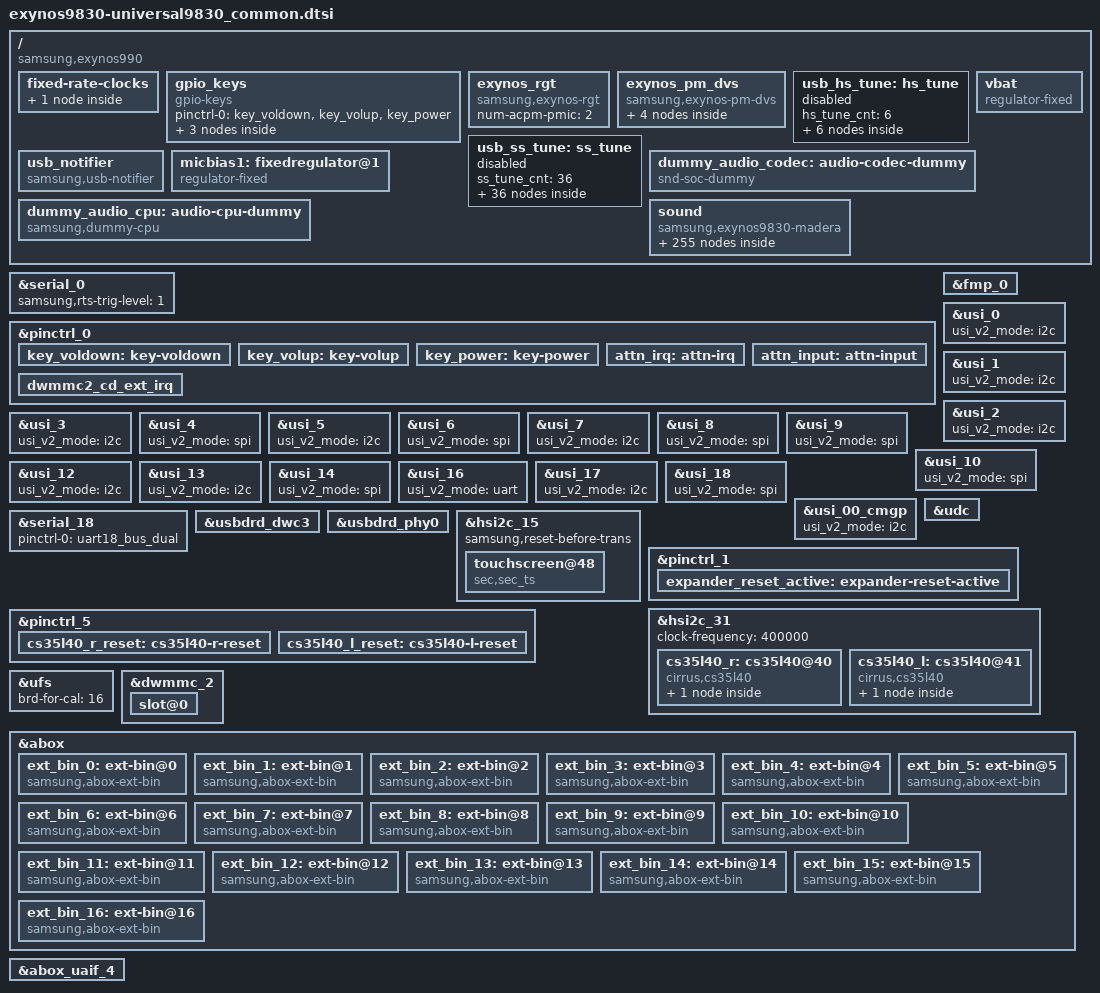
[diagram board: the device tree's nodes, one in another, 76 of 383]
/*
 * SAMSUNG EXYNOS9830 board device tree source
 *
 * Copyright (c) 2019 Samsung Electronics Co., Ltd.
 *		http://www.samsung.com
 *
 * This program is free software; you can redistribute it and/or modify
 * it under the terms of the GNU General Public License version 2 as
 * published by the Free Software Foundation.
*/

#include <dt-bindings/clock/exynos9830.h>
#include "battery_data_universal9830_max77705.dtsi"
#include "exynos9830-universal9830_if-pmic-max77705.dtsi"
#include <dt-bindings/pci/pci.h>

/ {
	compatible = "samsung,exynos990", "samsung,UNIVERSAL990";
	board_id = <0x0>;
	board_rev = <0x0>;

	fragment@model {
		target-path = "/";
		__overlay__ {
			#address-cells = <2>;
			#size-cells = <1>;

			fixed-rate-clocks {
				oscclk {
					compatible = "samsung,exynos9830-oscclk";
					clock-frequency = <26000000>;
				};
			};

			gpio_keys {
				status = "okay";
				compatible = "gpio-keys";
				pinctrl-names = "default";
				pinctrl-0 = <&key_voldown &key_volup &key_power>;

				button@2 {
					label = "gpio-keys: KEY_VOLUMEDOWN";
					linux,code = <114>;
					gpios = <&gpa0 4 0xf>;
				};
				button@3 {
					label = "gpio-keys: KEY_VOLUMEUP";
					linux,code = <115>;
					gpios = <&gpa0 3 0xf>;
				};
				button@4 {
					label = "gpio-keys: KEY_POWER";
					linux,code = <116>;
					gpios = <&gpa2 4 0xf>;
					gpio-key,wakeup = <1>;
				};
			};

			exynos_rgt {
				compatible = "samsung,exynos-rgt";
				num-acpm-pmic = <2>;
			};

			exynos_pm_dvs {
				compatible = "samsung,exynos-pm-dvs";
				vdd_lldo1 {
					regulator_name = "m_vdd_buck9";
					suspend_volt = <800000>;
					init_volt = <850000>;
					volt_range_step = <62500>;
				};

				vdd_lldo2 {
					regulator_name = "m_vdd_buck10";
					suspend_volt = <900000>;
					init_volt = <950000>;
					volt_range_step = <62500>;
				};

				vdd_lldo3 {
					regulator_name = "m_vdd_buck11";
					suspend_volt = <1250000>;
					init_volt = <1350000>;
					volt_range_step = <62500>;
				};
				vdd_mldo {
					regulator_name = "m_vdd_buck12";
					suspend_volt = <1850000>;
					init_volt = <2000000>;
					volt_range_step = <12500>;
				};
			};

			usb_hs_tune:hs_tune {
				status = "disabled";
				hs_tune_cnt = <6>;
				/* value = <device host> */
				hs_tune1 {
					tune_name = "tx_pre_emp";
					tune_value = <0x3 0x3>;
				};

				hs_tune2 {
					tune_name = "tx_vref";
					tune_value = <0xf 0xf>;
				};

				hs_tune3 {
					tune_name = "rx_sqrx";
					tune_value = <0x7 0x7>;
				};

				hs_tune4 {
					tune_name = "utmi_clk";
					tune_value = <0x1 0x1>;
				};

				hs_tune5 {
					tune_name = "compdis";
					tune_value = <0x7 0x7>;
				};

				hs_tune6 {
					tune_name = "tx_res";
					tune_value = <0x3 0x3>;
				};
			};

			usb_ss_tune:ss_tune {
				status = "disabled";
				ss_tune_cnt = <36>;
				/* value = <device host> */
				/* 0xffffffff means using default value */
				ss_tune1 {
					tune_name = "ssrx_sqhs_th_ss";
					tune_value = <0xffffffff 0xffffffff>;
				};

				ss_tune2 {
					tune_name = "ssrx_sqhs_th_ssp";
					tune_value = <0xffffffff 0xffffffff>;
				};

				ss_tune3 {
					tune_name = "ssrx_lfps_th";
					tune_value = <0xffffffff 0xffffffff>;
				};

				ss_tune4 {
					tune_name = "ssrx_adap_coef_sel";
					tune_value = <0xffffffff 0xffffffff>;
				};

				ss_tune5 {
					tune_name = "ssrx_mf_eq_psel_ctrl_ss";
					tune_value = <0xffffffff 0xffffffff>;
				};

				ss_tune6 {
					tune_name = "ssrx_mf_eq_psel_ctrl_ssp";
					tune_value = <0xffffffff 0xffffffff>;
				};

				ss_tune7 {
					tune_name = "ssrx_mf_eq_zsel_ctrl_ss";
					tune_value = <0xffffffff 0xffffffff>;
				};


				ss_tune8 {
					tune_name = "ssrx_mf_eq_zsel_ctrl_ssp";
					tune_value = <0xffffffff 0xffffffff>;
				};

				ss_tune9 {
					tune_name = "ssrx_hf_eq_rsel_ctrl_ss";
					tune_value = <0xffffffff 0xffffffff>;
				};

				ss_tune10 {
					tune_name = "ssrx_hf_eq_rsel_ctrl_ssp";
					tune_value = <0xffffffff 0xffffffff>;
				};

				ss_tune11 {
					tune_name = "ssrx_hf_eq_csel_ctrl_ss";
					tune_value = <0xffffffff 0xffffffff>;
				};

				ss_tune12 {
					tune_name = "ssrx_hf_eq_csel_ctrl_ssp";
					tune_value = <0xffffffff 0xffffffff>;
				};

				ss_tune13 {
					tune_name = "ssrx_dfe_1tap_ctrl_ss";
					tune_value = <0xffffffff 0xffffffff>;
				};

				ss_tune14 {
					tune_name = "ssrx_dfe_1tap_ctrl_ssp";
					tune_value = <0xffffffff 0xffffffff>;
				};

				ss_tune15 {
					tune_name = "ssrx_dfe_2tap_ctrl_ss";
					tune_value = <0xffffffff 0xffffffff>;
				};

				ss_tune16 {
					tune_name = "ssrx_dfe_2tap_ctrl_ssp";
					tune_value = <0xffffffff 0xffffffff>;
				};

				ss_tune17 {
					tune_name = "ssrx_dfe_3tap_ctrl_ss";
					tune_value = <0xffffffff 0xffffffff>;
				};

				ss_tune18 {
					tune_name = "ssrx_dfe_3tap_ctrl_ssp";
					tune_value = <0xffffffff 0xffffffff>;
				};

				ss_tune19 {
					tune_name = "ssrx_dfe_4tap_ctrl_ss";
					tune_value = <0xffffffff 0xffffffff>;
				};

				ss_tune20 {
					tune_name = "ssrx_dfe_4tap_ctrl_ssp";
					tune_value = <0xffffffff 0xffffffff>;
				};

				ss_tune21 {
					tune_name = "ssrx_dfe_5tap_ctrl_ss";
					tune_value = <0xffffffff 0xffffffff>;
				};

				ss_tune22 {
					tune_name = "ssrx_dfe_5tap_ctrl_ssp";
					tune_value = <0xffffffff 0xffffffff>;
				};

				ss_tune23 {
					tune_name = "ssrx_term_cal";
					tune_value = <0xffffffff 0xffffffff>;
				};

				ss_tune24 {
					tune_name = "sstx_amp_ss";
					tune_value = <0xffffffff 0xffffffff>;
				};

				ss_tune25 {
					tune_name = "sstx_deemp_ss";
					tune_value = <0xffffffff 0xffffffff>;
				};

				ss_tune26 {
					tune_name = "sstx_pre_shoot_ss";
					tune_value = <0xffffffff 0xffffffff>;
				};

				ss_tune27 {
					tune_name = "sstx_amp_ssp";
					tune_value = <0xffffffff 0xffffffff>;
				};

				ss_tune28 {
					tune_name = "sstx_deemp_ssp";
					tune_value = <0xffffffff 0xffffffff>;
				};

				ss_tune29 {
					tune_name = "sstx_pre_shoot_ssp";
					tune_value = <0xffffffff 0xffffffff>;
				};

				ss_tune30 {
					tune_name = "sstx_idrv_up";
					tune_value = <0xffffffff 0xffffffff>;
				};

				ss_tune31 {
					tune_name = "sstx_lfps_idrv_up";
					tune_value = <0xffffffff 0xffffffff>;
				};

				ss_tune32 {
					tune_name = "sstx_up_term";
					tune_value = <0xffffffff 0xffffffff>;
				};

				ss_tune33 {
					tune_name = "sstx_dn_term";
					tune_value = <0xffffffff 0xffffffff>;
				};

				ss_tune34 {
					tune_name = "rext_ovrd";
					tune_value = <0xffffffff 0xffffffff>;
				};

				ss_tune35 {
					tune_name = "ssrx_cdr_fbb_fine_ctrl_sp";
					tune_value = <0xffffffff 0xffffffff>;
				};

				ss_tune36 {
					tune_name = "ssrx_cdr_fbb_fine_ctrl_ssp";
					tune_value = <0xffffffff 0xffffffff>;
				};
			};

			usb_notifier {
				compatible = "samsung,usb-notifier";
				udc = <&udc>;

				usb-ldocontrol = <4>; /* Exynos9830 */
				disable_host_wakelock = <1>;
			};

			vbat: vbat {
				compatible = "regulator-fixed";
				regulator-name = "VBAT";
				regulator-min-microvolt = <4200000>;
				regulator-max-microvolt = <4200000>;
				regulator-boot-on;
			};

			micbias1: fixedregulator@1 {
				compatible = "regulator-fixed";
				regulator-name = "main_micbias_1p8";
				regulator-min-microvolt = <1800000>;
				regulator-max-microvolt = <1800000>;
				gpio = <&gpp2 7 0>;
				enable-active-high;
				vin-supply = <&buck12_reg>;
			};

			dummy_audio_codec: audio-codec-dummy {
				compatible = "snd-soc-dummy";
				#sound-dai-cells = <0>;
			};

			dummy_audio_cpu: audio-cpu-dummy {
				compatible = "samsung,dummy-cpu";
				#sound-dai-cells = <0>;
			};

			sound {
				compatible = "samsung,exynos9830-madera";

				clock-names = "xclkout";
				clocks = <&clock OSC_AUD>;

				MICBIAS1-supply = <&micbias1>;
				MICBIAS2-supply = <&ldo13_reg>;
				MICBIAS3-supply = <&ldo14_reg>;
				MICBIAS4-supply = <&ldo17_reg>;

				samsung,routing =
					"DMIC1", "MICBIAS1",
					"DMIC2", "MICBIAS2",
					"DMIC3", "MICBIAS3",
					"DMIC4", "MICBIAS4",
					"RECEIVER", "Left AMP SPK",
					"SPEAKER", "Right AMP SPK",
					"BLUETOOTH SPK", "ABOX UAIF3 Playback",
					"ABOX UAIF3 Capture", "BLUETOOTH MIC",
					"USB SPK", "ABOX USB Playback",
					"ABOX USB Capture", "USB MIC",
					"FWD SPK", "ABOX FWD Playback",
					"ABOX FWD Capture", "FWD MIC",
					"VTS Virtual Output", "VTS Virtual Output Mux",
					"PAD DPDM", "DMIC1",
					"PAD DPDM", "DMIC2",
					"PAD DPDM", "DMIC3",
					"PAD DPDM", "DMIC4";
				samsung,codec = <&cs35l40_l &cs35l40_r &vts>;
				samsung,prefix = "Left", "Right", "VTS";
				samsung,aux = <&abox_effect &abox_tplg>;

				rdma0 {
					cpu {
						sound-dai = <&abox_rdma_0 0>;
					};
					platform {
						sound-dai = <&abox_rdma_0 0>;
					};
					codec {
						sound-dai = <&dummy_audio_codec>;
					};
				};
				rdma1 {
					cpu {
						sound-dai = <&abox_rdma_1 0>;
					};
					platform {
						sound-dai = <&abox_rdma_1 0>;
					};
					codec {
						sound-dai = <&dummy_audio_codec>;
					};
				};
				rdma2 {
					cpu {
						sound-dai = <&abox_rdma_2 0>;
					};
					platform {
						sound-dai = <&abox_rdma_2 0>;
					};
					codec {
						sound-dai = <&dummy_audio_codec>;
					};
				};
				rdma3 {
					cpu {
						sound-dai = <&abox_rdma_3 0>;
					};
					platform {
						sound-dai = <&abox_rdma_3 0>;
					};
					codec {
						sound-dai = <&dummy_audio_codec>;
					};
				};
				rdma4 {
					cpu {
						sound-dai = <&abox_rdma_4 0>;
					};
					platform {
						sound-dai = <&abox_rdma_4 0>;
					};
					codec {
						sound-dai = <&dummy_audio_codec>;
					};
				};
				rdma5 {
					cpu {
						sound-dai = <&abox_rdma_5 0>;
					};
					platform {
						sound-dai = <&abox_rdma_5 0>;
					};
					codec {
						sound-dai = <&dummy_audio_codec>;
					};
				};
				rdma6 {
					cpu {
						sound-dai = <&abox_rdma_6 0>;
					};
					platform {
						sound-dai = <&abox_rdma_6 0>;
					};
					codec {
						sound-dai = <&dummy_audio_codec>;
					};
				};
				rdma7 {
					cpu {
						sound-dai = <&abox_rdma_7 0>;
					};
					platform {
						sound-dai = <&abox_rdma_7 0>;
					};
					codec {
						sound-dai = <&dummy_audio_codec>;
					};
				};
				rdma8 {
					cpu {
						sound-dai = <&abox_rdma_8 0>;
					};
					platform {
						sound-dai = <&abox_rdma_8 0>;
					};
					codec {
						sound-dai = <&dummy_audio_codec>;
					};
				};
				rdma9 {
					cpu {
						sound-dai = <&abox_rdma_9 0>;
					};
					platform {
						sound-dai = <&abox_rdma_9 0>;
					};
					codec {
						sound-dai = <&dummy_audio_codec>;
					};
				};
				rdma10 {
					cpu {
						sound-dai = <&abox_rdma_10 0>;
					};
					platform {
						sound-dai = <&abox_rdma_10 0>;
					};
					codec {
						sound-dai = <&dummy_audio_codec>;
					};
				};
				rdma11 {
					cpu {
						sound-dai = <&abox_rdma_11 0>;
					};
					platform {
						sound-dai = <&abox_rdma_11 0>;
					};
					codec {
						sound-dai = <&dummy_audio_codec>;
					};
				};
				wdma0 {
					cpu {
						sound-dai = <&abox_wdma_0 0>;
					};
					platform {
						sound-dai = <&abox_wdma_0 0>;
					};
					codec {
						sound-dai = <&dummy_audio_codec>;
					};
				};
				wdma1 {
					cpu {
						sound-dai = <&abox_wdma_1 0>;
					};
					platform {
						sound-dai = <&abox_wdma_1 0>;
					};
					codec {
						sound-dai = <&dummy_audio_codec>;
					};
				};
				wdma2 {
					cpu {
						sound-dai = <&abox_wdma_2 0>;
					};
					platform {
						sound-dai = <&abox_wdma_2 0>;
					};
					codec {
						sound-dai = <&dummy_audio_codec>;
					};
				};
				wdma3 {
					cpu {
						sound-dai = <&abox_wdma_3 0>;
					};
					platform {
						sound-dai = <&abox_wdma_3 0>;
					};
					codec {
						sound-dai = <&dummy_audio_codec>;
					};
				};
				wdma4 {
					cpu {
						sound-dai = <&abox_wdma_4 0>;
					};
					platform {
						sound-dai = <&abox_wdma_4 0>;
					};
					codec {
						sound-dai = <&dummy_audio_codec>;
					};
				};
				vts0 {
					cpu {
						sound-dai = <&vts 0>;
					};
					codec {
						sound-dai = <&dummy_audio_codec>;
					};
				};
				vts1 {
					cpu {
						sound-dai = <&vts 1>;
					};
					codec {
						sound-dai = <&dummy_audio_codec>;
					};
				};
				dp0_audio {
					cpu {
						sound-dai = <&displayport_adma 0>;
					};
					codec {
						sound-dai = <&dummy_audio_codec>;
					};
				};
				dp1_audio {
					cpu {
						sound-dai = <&displayport_adma 1 >;
					};
					codec {
						sound-dai = <&dummy_audio_codec>;
					};
				};
				dual0 {
					cpu {
						sound-dai = <&abox_dual_0>;
					};
					platform {
						sound-dai = <&abox_dual_0>;
					};
					codec {
						sound-dai = <&dummy_audio_codec>;
					};
				};
				dual1 {
					cpu {
						sound-dai = <&abox_dual_1>;
					};
					platform {
						sound-dai = <&abox_dual_1>;
					};
					codec {
						sound-dai = <&dummy_audio_codec>;
					};
				};
				dual2 {
					cpu {
						sound-dai = <&abox_dual_2>;
					};
					platform {
						sound-dai = <&abox_dual_2>;
					};
					codec {
						sound-dai = <&dummy_audio_codec>;
					};
				};
				dual3 {
					cpu {
						sound-dai = <&abox_dual_3>;
					};
					platform {
						sound-dai = <&abox_dual_3>;
					};
					codec {
						sound-dai = <&dummy_audio_codec>;
					};
				};
				dual4 {
					cpu {
						sound-dai = <&abox_dual_4>;
					};
					platform {
						sound-dai = <&abox_dual_4>;
					};
					codec {
						sound-dai = <&dummy_audio_codec>;
					};
				};
				ddma0 {
					cpu {
						sound-dai = <&abox_ddma_0>;
					};
					platform {
						sound-dai = <&abox_ddma_0>;
					};
					codec {
						sound-dai = <&dummy_audio_codec>;
					};
				};
				ddma1 {
					cpu {
						sound-dai = <&abox_ddma_1>;
					};
					platform {
						sound-dai = <&abox_ddma_1>;
					};
					codec {
						sound-dai = <&dummy_audio_codec>;
					};
				};
				ddma2 {
					cpu {
						sound-dai = <&abox_ddma_2>;
					};
					platform {
						sound-dai = <&abox_ddma_2>;
					};
					codec {
						sound-dai = <&dummy_audio_codec>;
					};
				};
				ddma3 {
					cpu {
						sound-dai = <&abox_ddma_3>;
					};
					platform {
						sound-dai = <&abox_ddma_3>;
					};
					codec {
						sound-dai = <&dummy_audio_codec>;
					};
				};
				ddma4 {
					cpu {
						sound-dai = <&abox_ddma_4>;
					};
					platform {
						sound-dai = <&abox_ddma_4>;
					};
					codec {
						sound-dai = <&dummy_audio_codec>;
					};
				};
				ddma5 {
					cpu {
						sound-dai = <&abox_ddma_5>;
					};
					platform {
						sound-dai = <&abox_ddma_5>;
					};
					codec {
						sound-dai = <&dummy_audio_codec>;
					};
				};
				uaif0 {
					format = "i2s";
					cpu {
						sound-dai = <&abox_uaif_0>;
					};
					codec {
						sound-dai = <&dummy_audio_codec>;
					};
				};
				uaif1 {
					format = "i2s";
					cpu {
						sound-dai = <&abox_uaif_1>;
					};
					codec {
						sound-dai = <&dummy_audio_codec>;
					};
				};
				uaif2 {
					format = "dsp_a";
					cpu {
						sound-dai = <&abox_uaif_2>;
					};
					codec {
						sound-dai = <&cs35l40_l 0 &cs35l40_r 0>;
					};
				};
				uaif3 {
					format = "i2s";
					cpu {
						sound-dai = <&abox_uaif_3>;
					};
					codec {
						sound-dai = <&dummy_audio_codec>;
					};
				};
				uaif4 {
					format = "i2s";
					cpu {
						sound-dai = <&abox_uaif_4>;
					};
					codec {
						sound-dai = <&dummy_audio_codec>;
					};
				};
				uaif5 {
					format = "i2s";
					cpu {
						sound-dai = <&abox_uaif_5>;
					};
					codec {
						sound-dai = <&dummy_audio_codec>;
					};
				};
				uaif6 {
					format = "dsp_a";
					bitclock-master;
					bitclock-inversion;
					frame-master;

					cpu {
						sound-dai = <&abox_uaif_6>;
					};
					codec {
						sound-dai = <&vts_s_lif 0>;
					};
				};
				dsif0 {
					format = "pdm";
					cpu {
						sound-dai = <&abox_dsif>;
					};
					codec {
						sound-dai = <&dummy_audio_codec>;
					};
				};
				sifs0 {
					cpu {
						sound-dai = <&abox 0>;
					};
					codec {
						sound-dai = <&dummy_audio_codec>;
					};
				};
				sifs1 {
					cpu {
						sound-dai = <&abox 1>;
					};
					codec {
						sound-dai = <&dummy_audio_codec>;
					};
				};
				sifs2 {
					cpu {
						sound-dai = <&abox 2>;
					};
					codec {
						sound-dai = <&dummy_audio_codec>;
					};
				};
				sifs3 {
					cpu {
						sound-dai = <&abox 3>;
					};
					codec {
						sound-dai = <&dummy_audio_codec>;
					};
				};
				sifs4 {
					cpu {
						sound-dai = <&abox 4>;
					};
					codec {
						sound-dai = <&dummy_audio_codec>;
					};
				};
				sifs5 {
					cpu {
						sound-dai = <&abox 5>;
					};
					codec {
						sound-dai = <&dummy_audio_codec>;
					};
				};
				nsrc0 {
					cpu {
						sound-dai = <&abox 6>;
					};
					codec {
						sound-dai = <&dummy_audio_codec>;
					};
				};
				nsrc1 {
					cpu {
						sound-dai = <&abox 7>;
					};
					codec {
						sound-dai = <&dummy_audio_codec>;
					};
				};
				nsrc2 {
					cpu {
						sound-dai = <&abox 8>;
					};
					codec {
						sound-dai = <&dummy_audio_codec>;
					};
				};
				nsrc3 {
					cpu {
						sound-dai = <&abox 9>;
					};
					codec {
						sound-dai = <&dummy_audio_codec>;
					};
				};
				nsrc4 {
					cpu {
						sound-dai = <&abox 10>;
					};
					codec {
						sound-dai = <&dummy_audio_codec>;
					};
				};
				rdma0_be {
					cpu {
						sound-dai = <&abox_rdma_0 1>;
					};
					platform {
						sound-dai = <&abox_rdma_0 1>;
					};
					codec {
						sound-dai = <&dummy_audio_codec>;
					};
				};
				rdma1_be {
					cpu {
						sound-dai = <&abox_rdma_1 1>;
					};
					platform {
						sound-dai = <&abox_rdma_1 1>;
					};
					codec {
						sound-dai = <&dummy_audio_codec>;
					};
				};
				rdma2_be {
					cpu {
						sound-dai = <&abox_rdma_2 1>;
					};
					platform {
						sound-dai = <&abox_rdma_2 1>;
					};
					codec {
						sound-dai = <&dummy_audio_codec>;
					};
				};
				rdma3_be {
					cpu {
						sound-dai = <&abox_rdma_3 1>;
					};
					platform {
						sound-dai = <&abox_rdma_3 1>;
					};
					codec {
						sound-dai = <&dummy_audio_codec>;
					};
				};
				rdma4_be {
					cpu {
						sound-dai = <&abox_rdma_4 1>;
					};
					platform {
						sound-dai = <&abox_rdma_4 1>;
					};
					codec {
						sound-dai = <&dummy_audio_codec>;
					};
				};
				rdma5_be {
					cpu {
						sound-dai = <&abox_rdma_5 1>;
					};
					platform {
						sound-dai = <&abox_rdma_5 1>;
					};
					codec {
						sound-dai = <&dummy_audio_codec>;
					};
				};
				rdma6_be {
					cpu {
						sound-dai = <&abox_rdma_6 1>;
					};
					platform {
						sound-dai = <&abox_rdma_6 1>;
					};
					codec {
						sound-dai = <&dummy_audio_codec>;
					};
				};
				rdma7_be {
					cpu {
						sound-dai = <&abox_rdma_7 1>;
					};
					platform {
						sound-dai = <&abox_rdma_7 1>;
					};
					codec {
						sound-dai = <&dummy_audio_codec>;
					};
				};
				rdma8_be {
					cpu {
						sound-dai = <&abox_rdma_8 1>;
					};
					platform {
						sound-dai = <&abox_rdma_8 1>;
					};
					codec {
						sound-dai = <&dummy_audio_codec>;
					};
				};
				rdma9_be {
					cpu {
						sound-dai = <&abox_rdma_9 1>;
					};
					platform {
						sound-dai = <&abox_rdma_9 1>;
					};
					codec {
						sound-dai = <&dummy_audio_codec>;
					};
				};
				rdma10_be {
					cpu {
						sound-dai = <&abox_rdma_10 1>;
					};
					platform {
						sound-dai = <&abox_rdma_10 1>;
					};
					codec {
						sound-dai = <&dummy_audio_codec>;
					};
				};
				rdma11_be {
					cpu {
						sound-dai = <&abox_rdma_11 1>;
					};
					platform {
						sound-dai = <&abox_rdma_11 1>;
					};
					codec {
						sound-dai = <&dummy_audio_codec>;
					};
				};
				wdma0_be {
					cpu {
						sound-dai = <&abox_wdma_0 1>;
					};
					platform {
						sound-dai = <&abox_wdma_0 1>;
					};
					codec {
						sound-dai = <&dummy_audio_codec>;
					};
				};
				wdma1_be {
					cpu {
						sound-dai = <&abox_wdma_1 1>;
					};
					platform {
						sound-dai = <&abox_wdma_1 1>;
					};
					codec {
						sound-dai = <&dummy_audio_codec>;
					};
				};
				wdma2_be {
					cpu {
						sound-dai = <&abox_wdma_2 1>;
					};
					platform {
						sound-dai = <&abox_wdma_2 1>;
					};
					codec {
						sound-dai = <&dummy_audio_codec>;
					};
				};
				wdma3_be {
					cpu {
						sound-dai = <&abox_wdma_3 1>;
					};
					platform {
						sound-dai = <&abox_wdma_3 1>;
					};
					codec {
						sound-dai = <&dummy_audio_codec>;
					};
				};
				wdma4_be {
					cpu {
						sound-dai = <&abox_wdma_4 1>;
					};
					platform {
						sound-dai = <&abox_wdma_4 1>;
					};
					codec {
						sound-dai = <&dummy_audio_codec>;
					};
				};
				usb {
					cpu {
						sound-dai = <&abox 16>;
					};
					codec {
						sound-dai = <&dummy_audio_codec>;
					};
				};
				fwd {
					cpu {
						sound-dai = <&abox 17>;
					};
					codec {
						sound-dai = <&dummy_audio_codec>;
					};
				};
			};
		}; /* end of __overlay__ */
	}; /* end of fragment */
}; /* end of root */

&serial_0 {
	samsung,rts-trig-level = <1>;
	status = "okay";
};

&pinctrl_0 {
	key_voldown: key-voldown {
		samsung,pins = "gpa0-4";
		samsung,pin-function = <0xf>;
		samsung,pin-pud = <0>;
		samsung,pin-drv = <0>;
	};

	key_volup: key-volup {
		samsung,pins = "gpa0-3";
		samsung,pin-function = <0xf>;
		samsung,pin-pud = <0>;
		samsung,pin-drv = <0>;
	};

	key_power: key-power {
		samsung,pins = "gpa2-4";
		samsung,pin-function = <0xf>;
		samsung,pin-pud = <0>;
		samsung,pin-drv = <0>;
	};

	attn_irq: attn-irq {
		samsung,pins = "gpa1-0";
		samsung,pin-function = <0xf>;
		samsung,pin-pud = <0>;
		samsung,pin-drv = <0>;
	};

	attn_input: attn-input {
		samsung,pins = "gpa1-0";
		samsung,pin-function = <0>;
		samsung,pin-pud = <1>;
	};
};

&fmp_0 {
	exynos,block-type = "sda";
	exynos,fips-block_offset = <5>;
};

&usi_0 {
	usi_v2_mode = "i2c";
	status = "okay";
};

&usi_1 {
	usi_v2_mode = "i2c";
	status = "okay";
};

&usi_2 {
	usi_v2_mode = "i2c";
	status = "okay";
};

&usi_3 {
	usi_v2_mode = "i2c";
	status = "okay";
};

&usi_4 {
	usi_v2_mode = "spi";
	status = "okay";
};

&usi_5 {
	usi_v2_mode = "i2c";
	status = "okay";
};

&usi_6 {
	usi_v2_mode = "spi";
	status = "okay";
};

&usi_7 {
	usi_v2_mode = "i2c";
	status = "okay";
};

&usi_8 {
	usi_v2_mode = "spi";
	status = "okay";
};

&usi_9 {
	usi_v2_mode = "spi";
	status = "okay";
};

&usi_10 {
	usi_v2_mode = "spi";
	status = "okay";
};

&usi_12 {
	usi_v2_mode = "i2c";
	status = "okay";
};

&usi_13 {
	usi_v2_mode = "i2c";
	status = "okay";
};

&usi_14 {
	usi_v2_mode = "spi";
	status = "okay";
};

&usi_16 {
	usi_v2_mode = "uart";
	status = "okay";
};

&usi_17 {
	usi_v2_mode = "i2c";
	status = "okay";
};

&usi_18 {
	usi_v2_mode = "spi";
	status = "okay";
};

&usi_00_cmgp {
	usi_v2_mode = "i2c";
	status = "okay";
};

&serial_18 {
	pinctrl-0 = <&uart18_bus_dual>;
};

&udc {
	status = "okay";
};

&usbdrd_dwc3 {
	status = "okay";

	dr_mode = "otg";
	maximum-speed = "super-speed-plus";
	snps,quirk-frame-length-adjustment = <0x20>;
	/* snps,u1u2_exitfail_quirk; */
	/* ux_exit_in_px should be defined in MK, LT */
	snps,ux_exit_in_px_quirk;
	/* elastic_buf_mode_quirk should be defined in MK */
	snps,elastic_buf_mode_quirk;
	usb3-lpm-capable;
	snps,usb3_lpm_capable;
	adj-sof-accuracy = <1>;
	/*
	 * dis-u2-freeclk-exists-quirk, dis_u2_susphy_quirk are alternative.
	 * One of them should be selected
	 */
	snps,dis-u2-freeclk-exists-quirk;
	/*snps,dis_u2_susphy_quirk;*/
	samsung,no-extra-delay;
	usb_host_device_timeout = <200>; /* Max value */

	usb_audio_offloading = <1>;
	abox = <&abox>;
	/* check susphy support */
	xhci_l2_support = <1>;
	xhci_use_uram_for_audio = <1>;
};

&usbdrd_phy0 {
	status = "okay";

	/*
	pinctrl-names = "default";
	pinctrl-0 = <&phy_port>;
	*/
	phy,gpio_phy_port = <&gpm26 0 0x0>;
	hs_tune_param = <&usb_hs_tune>;
	ss_tune_param = <&usb_ss_tune>;
};

&hsi2c_15 {
	#address-cells = <1>;
	#size-cells = <0>;
	status = "okay";
	samsung,reset-before-trans;
	touchscreen@48 {
		compatible = "sec,sec_ts";
		reg = <0x48>;
		pinctrl-names = "on_state", "off_state";
		pinctrl-0 = <&attn_irq>;
		pinctrl-1 = <&attn_input>;
		pressure-sensor = "Y";
		sec,irq_gpio = <&gpa1 0 0>;
		sec,irq_type = <8200>;
		sec,max_coords = <4095 4095>;
		sec,mis_cal_check = <1>;
		sec,regulator_dvdd = "m_vdd_ldo19";
		sec,regulator_avdd = "m_vdd_ldo27";
		sec,regulator_boot_on;
		sec,always_lpmode = <1>;
		sec,project_name = "Picasso", "GS11";
		sec,firmware_name = "tsp_sec/y761_dream1.fw", "tsp_sec/y761_dream1.fw";
	};
};

&pinctrl_0 {
	dwmmc2_cd_ext_irq: dwmmc2_cd_ext_irq {
		samsung,pins = "gpa1-5";
		samsung,pin-function = <0xf>;
		samsung,pin-pud = <3>;
		samsung,pin-drv = <4>;
	};
};

&pinctrl_1 {
	expander_reset_active: expander-reset-active {
	       samsung,pins = "gpm21-0";
	       samsung,pin-function = <1>;
	       samsung,pin-pud = <0>;
	       samsung,pin-val = <1>;
       };
};

&pinctrl_5 {
	cs35l40_r_reset: cs35l40-r-reset {
		samsung,pins ="gpb2-5";
		samsung,pin-con-pdn =<3>;
		samsung,pin-pud-pdn = <0>;
	};
	cs35l40_l_reset: cs35l40-l-reset {
		samsung,pins ="gpb2-4";
		samsung,pin-con-pdn =<3>;
		samsung,pin-pud-pdn = <0>;
	};
};

&hsi2c_31 {
	#address-cells = <1>;
	#size-cells = <0>;
	status = "okay";
	clock-frequency = <400000>;
	cs35l40_r: cs35l40@40 {
		#sound-dai-cells = <1>;
		compatible = "cirrus,cs35l40";
		reg = <0x40>;
		interrupt-parent = <&gpm24>;
		interrupts = <0 0 0>;
		pinctrl-names = "default";
		pinctrl-0 = <&cs35l40_r_reset>;
		reset-gpios = <&gpb2 5 0>;
		VA-supply = <&s_ldo4_reg>;
		VP-supply = <&vbat>;

		cirrus,right-channel-amp;

		cirrus,gpio-config2 {
			cirrus,gpio-src-select = <0x4>;
			cirrus,gpio-output-enable;
		};
	};

	cs35l40_l: cs35l40@41 {
		#sound-dai-cells = <1>;
		compatible = "cirrus,cs35l40";
		reg = <0x41>;
		interrupt-parent = <&gpm24>;
		interrupts = <0 0 0>;
		pinctrl-names = "default";
		pinctrl-0 = <&cs35l40_l_reset>;
		reset-gpios = <&gpb2 4 0>;
		VA-supply = <&s_ldo4_reg>;
		VP-supply = <&vbat>;

		cirrus,gpio-config2 {
			cirrus,gpio-src-select = <0x4>;
			cirrus,gpio-output-enable;
		};
	};
};

&ufs {
	/* board type for UFS CAL */
	brd-for-cal = /bits/ 8 <16>;  /* (1:SMDK, 16:UNIV) board */

};

&dwmmc_2 {
	#address-cells = <2>;
	#size-cells = <1>;
	status = "okay";
	num-slots = <1>;
	supports-4bit;
	supports-cmd23;
	supports-erase;
	supports-highspeed;
	sd-uhs-sdr50;
	sd-uhs-sdr104;
	card-detect-gpio;
	bypass-for-allpass;
	use-fine-tuning;
	card-init-hwacg-ctrl;
	skip-init-mmc-scan;
	fifo-depth = <0x40>;
	qos_dvfs_level = <400000>;
	desc-size = <4>;
	ssc-rate = <3>;
	card-detect-delay = <200>;
	data-timeout = <200>;
	hto-timeout = <80>;
	samsung,dw-mshc-ciu-div = <3>;
	clock-frequency = <800000000>;
	samsung,dw-mshc-sdr-timing = <3 0 2 0>;
	samsung,dw-mshc-ddr-timing = <3 0 2 1>;
	samsung,dw-mshc-sdr50-timing = <3 0 4 2>;
	samsung,dw-mshc-sdr104-timing = <3 0 3 0>;

	num-ref-clks = <9>;
	ciu_clkin = <25 50 50 25 50 100 200 50 50>;

	/* Swapping clock drive strength */
	clk-drive-number = <6>;
	pinctrl-names = "default",
		"fast-slew-rate-1x",
		"fast-slew-rate-1_5x",
		"fast-slew-rate-2x",
		"fast-slew-rate-2_5x",
		"fast-slew-rate-3x",
		"fast-slew-rate-4x",
		"pins-as-pdn",
		"pins-as-func";
	pinctrl-0 = <&sd2_clk &sd2_cmd &sd2_bus1 &sd2_bus4 &dwmmc2_cd_ext_irq>;
	pinctrl-1 = <&sd2_clk_fast_slew_rate_1x>;
	pinctrl-2 = <&sd2_clk_fast_slew_rate_1_5x>;
	pinctrl-3 = <&sd2_clk_fast_slew_rate_2x>;
	pinctrl-4 = <&sd2_clk_fast_slew_rate_2_5x>;
	pinctrl-5 = <&sd2_clk_fast_slew_rate_3x>;
	pinctrl-6 = <&sd2_clk_fast_slew_rate_4x>;
	pinctrl-7 = <&sd2_pins_as_pdn>;
	pinctrl-8 = <&sd2_clk &sd2_cmd &sd2_bus1 &sd2_bus4>;

	card-detect = <&gpa1 5 0xf>;
	slot@0 {
		reg = <0>;
		bus-width = <4>;
		disable-wp;
	};
};

&abox {
	ext_bin_0: ext-bin@0 {
		compatible = "samsung,abox-ext-bin";
		samsung,name = "APSV_AUDIO_SLSI.bin";
		samsung,area = <1>;
		samsung,offset = <0x582000>;
		samsung,changable;
	};

	ext_bin_1: ext-bin@1 {
		compatible = "samsung,abox-ext-bin";
		samsung,name = "AP_AUDIO_SLSI.bin";
		samsung,area = <1>;
		samsung,offset = <0x5ea000>;
		samsung,changable;
	};

	ext_bin_2: ext-bin@2 {
		compatible = "samsung,abox-ext-bin";
		samsung,name = "APBargeIn_AUDIO_SLSI.bin";
		samsung,area = <1>;
		samsung,offset = <0x652000>;
		samsung,changable;
	};

	ext_bin_3: ext-bin@3 {
		compatible = "samsung,abox-ext-bin";
		samsung,name = "APBiBF_AUDIO_SLSI.bin";
		samsung,area = <1>;
		samsung,offset = <0x655000>;
		samsung,changable;
	};

	ext_bin_4: ext-bin@4 {
		compatible = "samsung,abox-ext-bin";
		samsung,name = "APDV_AUDIO_SLSI.bin";
		samsung,area = <1>;
		samsung,offset = <0x656000>;
		samsung,changable;
	};

	ext_bin_5: ext-bin@5 {
		compatible = "samsung,abox-ext-bin";
		samsung,name = "SoundBoosterParam.bin";
		samsung,area = <1>;
		samsung,offset = <0x6d6000>;
		samsung,changable;
	};

	ext_bin_6: ext-bin@6 {
		compatible = "samsung,abox-ext-bin";
		samsung,name = "bidirmic.bin";
		samsung,area = <1>;
		samsung,offset = <0x700000>;
	};

	ext_bin_7: ext-bin@7 {
		compatible = "samsung,abox-ext-bin";
		samsung,name = "txse1.bin";
		samsung,area = <1>;
		samsung,offset = <0x1800000>;
	};

	ext_bin_8: ext-bin@8 {
		compatible = "samsung,abox-ext-bin";
		samsung,name = "txse2.bin";
		samsung,area = <1>;
		samsung,offset = <0x19e4000>;
	};

	ext_bin_9: ext-bin@9 {
		compatible = "samsung,abox-ext-bin";
		samsung,name = "volumemonitor.bin";
		samsung,area = <1>;
		samsung,offset = <0x1a16000>;
	};

	ext_bin_10: ext-bin@10 {
		compatible = "samsung,abox-ext-bin";
		samsung,name = "sv.bin";
		samsung,area = <1>;
		samsung,offset = <0x1a2f000>;
	};

	ext_bin_11: ext-bin@11 {
		compatible = "samsung,abox-ext-bin";
		samsung,name = "rxse.bin";
		samsung,area = <1>;
		samsung,offset = <0x1e4f000>;
	};

	ext_bin_12: ext-bin@12 {
		compatible = "samsung,abox-ext-bin";
		samsung,name = "sb_music.bin";
		samsung,area = <1>;
		samsung,offset = <0x1eff000>;
	};

	ext_bin_13: ext-bin@13 {
		compatible = "samsung,abox-ext-bin";
		samsung,name = "sb_others.bin";
		samsung,area = <1>;
		samsung,offset = <0x1fdd000>;
	};

	ext_bin_14: ext-bin@14 {
		compatible = "samsung,abox-ext-bin";
		samsung,name = "sb_ll.bin";
		samsung,area = <1>;
		samsung,offset = <0x20bb000>;
	};

	ext_bin_15: ext-bin@15 {
		compatible = "samsung,abox-ext-bin";
		samsung,name = "listenbackeffect.bin";
		samsung,area = <1>;
		samsung,offset = <0x2199000>;
	};

	ext_bin_16: ext-bin@16 {
		compatible = "samsung,abox-ext-bin";
		samsung,name = "a2dpcom.bin";
		samsung,area = <1>;
		samsung,offset = <0x21fd000>;
	};
};

&abox_uaif_4 {
	pinctrl-names;
};

